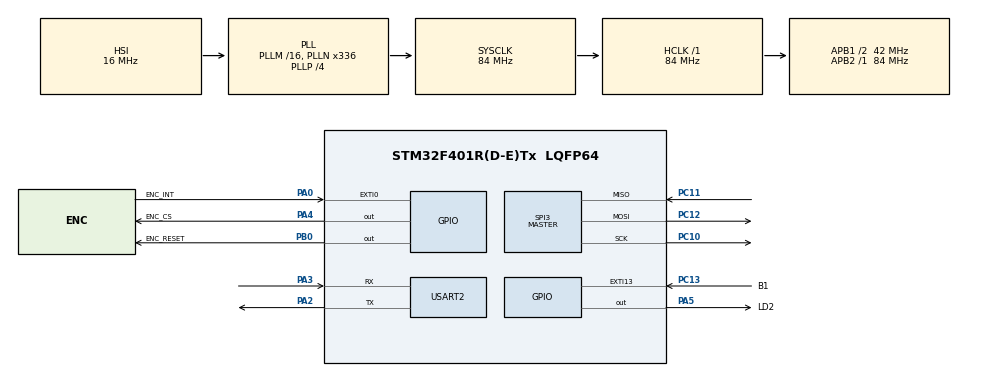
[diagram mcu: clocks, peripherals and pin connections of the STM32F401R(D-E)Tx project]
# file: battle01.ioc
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Mcu.Family=STM32F4
Mcu.Name=STM32F401R(D-E)Tx
Mcu.Package=LQFP64
NVIC.EXTI0_IRQn=true\:6\:0\:true\:false\:true\:true\:true\:true
NVIC.EXTI15_10_IRQn=true\:7\:0\:true\:false\:true\:true\:true\:true
NVIC.PriorityGroup=NVIC_PRIORITYGROUP_4
NVIC.TIM5_IRQn=true\:15\:0\:false\:false\:true\:false\:true\:true
NVIC.TimeBase=TIM5_IRQn
NVIC.TimeBaseIP=TIM5
PA0-WKUP.GPIO_Label=ENC_INT
PA0-WKUP.GPIO_ModeDefaultEXTI=GPIO_MODE_IT_FALLING
PA0-WKUP.GPIO_PuPd=GPIO_PULLUP
PA0-WKUP.Signal=GPXTI0
PA2.Mode=Asynchronous
PA2.Signal=USART2_TX
PA3.Mode=Asynchronous
PA3.Signal=USART2_RX
PA4.GPIO_Label=ENC_CS
PA4.PinState=GPIO_PIN_SET
PA4.Signal=GPIO_Output
PA5.GPIO_Label=LD2
PA5.Signal=GPIO_Output
PB0.GPIO_Label=ENC_RESET
PB0.PinState=GPIO_PIN_SET
PB0.Signal=GPIO_Output
PC10.GPIO_Speed=GPIO_SPEED_FREQ_MEDIUM
PC10.Mode=Full_Duplex_Master
PC10.Signal=SPI3_SCK
PC11.GPIO_Speed=GPIO_SPEED_FREQ_MEDIUM
PC11.Mode=Full_Duplex_Master
PC11.Signal=SPI3_MISO
PC12.GPIO_Speed=GPIO_SPEED_FREQ_MEDIUM
PC12.Mode=Full_Duplex_Master
PC12.Signal=SPI3_MOSI
PC13-ANTI_TAMP.GPIO_Label=B1
PC13-ANTI_TAMP.GPIO_ModeDefaultEXTI=GPIO_MODE_IT_FALLING
PC13-ANTI_TAMP.Signal=GPXTI13
ProjectManager.HeapSize=0x200
ProjectManager.StackSize=0x400
ProjectManager.TargetToolchain=STM32CubeIDE
RCC.48MHZClocksFreq_Value=84000000
RCC.AHBFreq_Value=84000000
RCC.APB1CLKDivider=RCC_HCLK_DIV2
RCC.APB1Freq_Value=42000000
RCC.APB1TimFreq_Value=84000000
RCC.APB2Freq_Value=84000000
RCC.APB2TimFreq_Value=84000000
RCC.CortexFreq_Value=84000000
RCC.HCLKFreq_Value=84000000
RCC.HSE_VALUE=25000000
RCC.HSI_VALUE=16000000
RCC.LSE_VALUE=32768
RCC.PLLN=336
RCC.PLLP=RCC_PLLP_DIV4
RCC.SYSCLKFreq_VALUE=84000000
RCC.SYSCLKSource=RCC_SYSCLKSOURCE_PLLCLK
RCC.VCOOutputFreq_Value=336000000
SPI3.BaudRatePrescaler=SPI_BAUDRATEPRESCALER_8
SPI3.Direction=SPI_DIRECTION_2LINES
SPI3.Mode=SPI_MODE_MASTER
SPI3.VirtualType=VM_MASTER
USART2.VirtualMode=VM_ASYNC
VP_SYS_VS_tim5.Mode=TIM5
board=custom

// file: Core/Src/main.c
/* USER CODE BEGIN Header */
/**
  ******************************************************************************
  * @file           : main.c
  * @brief          : Main program body
  ******************************************************************************
  * @attention
  *
  * Copyright (c) 2026 STMicroelectronics.
  * All rights reserved.
  *
  * This software is licensed under terms that can be found in the LICENSE file
  * in the root directory of this software component.
  * If no LICENSE file comes with this software, it is provided AS-IS.
  *
  ******************************************************************************
  */
/* USER CODE END Header */
#include "main.h"

/* USER CODE BEGIN Includes */
#include "app.h"
#include "app_log.h"
/* USER CODE END Includes */

SPI_HandleTypeDef hspi3;

UART_HandleTypeDef huart2;

void SystemClock_Config(void);
static void MX_GPIO_Init(void);
static void MX_SPI3_Init(void);
static void MX_USART2_UART_Init(void);

int main(void)
{

  /* MCU Configuration--------------------------------------------------------*/

  /* Reset of all peripherals, Initializes the Flash interface and the Systick. */
  HAL_Init();

  /* Configure the system clock */
  SystemClock_Config();

  /* Initialize all configured peripherals */
  MX_GPIO_Init();
  MX_SPI3_Init();
  MX_USART2_UART_Init();
  /* USER CODE BEGIN 2 */
  /* Creates the tasks and starts the FreeRTOS scheduler; does not return. */
  app_start();
  /* USER CODE END 2 */

  /* Infinite loop */
  while (1)
  {

  }
}

void SystemClock_Config(void)
{
  RCC_OscInitTypeDef RCC_OscInitStruct = {0};
  RCC_ClkInitTypeDef RCC_ClkInitStruct = {0};

  /** Configure the main internal regulator output voltage
  */
  __HAL_RCC_PWR_CLK_ENABLE();
  __HAL_PWR_VOLTAGESCALING_CONFIG(PWR_REGULATOR_VOLTAGE_SCALE2);

  /** Initializes the RCC Oscillators according to the specified parameters
  * in the RCC_OscInitTypeDef structure.
  */
  RCC_OscInitStruct.OscillatorType = RCC_OSCILLATORTYPE_HSI;
  RCC_OscInitStruct.HSIState = RCC_HSI_ON;
  RCC_OscInitStruct.HSICalibrationValue = RCC_HSICALIBRATION_DEFAULT;
  RCC_OscInitStruct.PLL.PLLState = RCC_PLL_ON;
  RCC_OscInitStruct.PLL.PLLSource = RCC_PLLSOURCE_HSI;
  RCC_OscInitStruct.PLL.PLLM = 16;
  RCC_OscInitStruct.PLL.PLLN = 336;
  RCC_OscInitStruct.PLL.PLLP = RCC_PLLP_DIV4;
  RCC_OscInitStruct.PLL.PLLQ = 4;
  if (HAL_RCC_OscConfig(&RCC_OscInitStruct) != HAL_OK)
  {
    Error_Handler();
  }

  /** Initializes the CPU, AHB and APB buses clocks
  */
  RCC_ClkInitStruct.ClockType = RCC_CLOCKTYPE_HCLK|RCC_CLOCKTYPE_SYSCLK
                              |RCC_CLOCKTYPE_PCLK1|RCC_CLOCKTYPE_PCLK2;
  RCC_ClkInitStruct.SYSCLKSource = RCC_SYSCLKSOURCE_PLLCLK;
  RCC_ClkInitStruct.AHBCLKDivider = RCC_SYSCLK_DIV1;
  RCC_ClkInitStruct.APB1CLKDivider = RCC_HCLK_DIV2;
  RCC_ClkInitStruct.APB2CLKDivider = RCC_HCLK_DIV1;

  if (HAL_RCC_ClockConfig(&RCC_ClkInitStruct, FLASH_LATENCY_2) != HAL_OK)
  {
    Error_Handler();
  }
}

static void MX_SPI3_Init(void)
{

  /* SPI3 parameter configuration*/
  hspi3.Instance = SPI3;
  hspi3.Init.Mode = SPI_MODE_MASTER;
  hspi3.Init.Direction = SPI_DIRECTION_2LINES;
  hspi3.Init.DataSize = SPI_DATASIZE_8BIT;
  hspi3.Init.CLKPolarity = SPI_POLARITY_LOW;
  hspi3.Init.CLKPhase = SPI_PHASE_1EDGE;
  hspi3.Init.NSS = SPI_NSS_SOFT;
  hspi3.Init.BaudRatePrescaler = SPI_BAUDRATEPRESCALER_8;
  hspi3.Init.FirstBit = SPI_FIRSTBIT_MSB;
  hspi3.Init.TIMode = SPI_TIMODE_DISABLE;
  hspi3.Init.CRCCalculation = SPI_CRCCALCULATION_DISABLE;
  hspi3.Init.CRCPolynomial = 10;
  if (HAL_SPI_Init(&hspi3) != HAL_OK)
  {
    Error_Handler();
  }

}

static void MX_USART2_UART_Init(void)
{

  huart2.Instance = USART2;
  huart2.Init.BaudRate = 115200;
  huart2.Init.WordLength = UART_WORDLENGTH_8B;
  huart2.Init.StopBits = UART_STOPBITS_1;
  huart2.Init.Parity = UART_PARITY_NONE;
  huart2.Init.Mode = UART_MODE_TX_RX;
  huart2.Init.HwFlowCtl = UART_HWCONTROL_NONE;
  huart2.Init.OverSampling = UART_OVERSAMPLING_16;
  if (HAL_UART_Init(&huart2) != HAL_OK)
  {
    Error_Handler();
  }

}

static void MX_GPIO_Init(void)
{
  GPIO_InitTypeDef GPIO_InitStruct = {0};

  /* GPIO Ports Clock Enable */
  __HAL_RCC_GPIOC_CLK_ENABLE();
  __HAL_RCC_GPIOA_CLK_ENABLE();
  __HAL_RCC_GPIOB_CLK_ENABLE();

  /*Configure GPIO pin Output Level */
  HAL_GPIO_WritePin(ENC_CS_GPIO_Port, ENC_CS_Pin, GPIO_PIN_SET);

  /*Configure GPIO pin Output Level */
  HAL_GPIO_WritePin(LD2_GPIO_Port, LD2_Pin, GPIO_PIN_RESET);

  /*Configure GPIO pin Output Level */
  HAL_GPIO_WritePin(ENC_RESET_GPIO_Port, ENC_RESET_Pin, GPIO_PIN_SET);

  /*Configure GPIO pin : B1_Pin */
  GPIO_InitStruct.Pin = B1_Pin;
  GPIO_InitStruct.Mode = GPIO_MODE_IT_FALLING;
  GPIO_InitStruct.Pull = GPIO_NOPULL;
  HAL_GPIO_Init(B1_GPIO_Port, &GPIO_InitStruct);

  /*Configure GPIO pin : ENC_INT_Pin */
  GPIO_InitStruct.Pin = ENC_INT_Pin;
  GPIO_InitStruct.Mode = GPIO_MODE_IT_FALLING;
  GPIO_InitStruct.Pull = GPIO_PULLUP;
  HAL_GPIO_Init(ENC_INT_GPIO_Port, &GPIO_InitStruct);

  /*Configure GPIO pins : ENC_CS_Pin LD2_Pin */
  GPIO_InitStruct.Pin = ENC_CS_Pin|LD2_Pin;
  GPIO_InitStruct.Mode = GPIO_MODE_OUTPUT_PP;
  GPIO_InitStruct.Pull = GPIO_NOPULL;
  GPIO_InitStruct.Speed = GPIO_SPEED_FREQ_LOW;
  HAL_GPIO_Init(GPIOA, &GPIO_InitStruct);

  /*Configure GPIO pin : ENC_RESET_Pin */
  GPIO_InitStruct.Pin = ENC_RESET_Pin;
  GPIO_InitStruct.Mode = GPIO_MODE_OUTPUT_PP;
  GPIO_InitStruct.Pull = GPIO_NOPULL;
  GPIO_InitStruct.Speed = GPIO_SPEED_FREQ_LOW;
  HAL_GPIO_Init(ENC_RESET_GPIO_Port, &GPIO_InitStruct);

  /* EXTI interrupt init*/
  HAL_NVIC_SetPriority(EXTI0_IRQn, 6, 0);
  HAL_NVIC_EnableIRQ(EXTI0_IRQn);

  HAL_NVIC_SetPriority(EXTI15_10_IRQn, 7, 0);
  HAL_NVIC_EnableIRQ(EXTI15_10_IRQn);

}

void HAL_TIM_PeriodElapsedCallback(TIM_HandleTypeDef *htim)
{
  if (htim->Instance == TIM5)
  {
    HAL_IncTick();
  }
}

void Error_Handler(void)
{
  /* USER CODE BEGIN Error_Handler_Debug */
  /* User can add his own implementation to report the HAL error return state */
  app_panic("Error_Handler", NULL, 0);
  /* USER CODE END Error_Handler_Debug */
}
